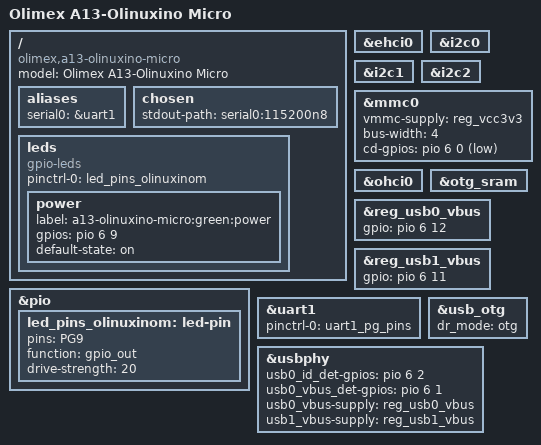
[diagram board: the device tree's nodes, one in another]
/*
 * Copyright 2012 Maxime Ripard <maxime.ripard@free-electrons.com>
 * Copyright 2013 Hans de Goede <hdegoede@redhat.com>
 *
 * This file is dual-licensed: you can use it either under the terms
 * of the GPL or the X11 license, at your option. Note that this dual
 * licensing only applies to this file, and not this project as a
 * whole.
 *
 *  a) This file is free software; you can redistribute it and/or
 *     modify it under the terms of the GNU General Public License as
 *     published by the Free Software Foundation; either version 2 of the
 *     License, or (at your option) any later version.
 *
 *     This file is distributed in the hope that it will be useful,
 *     but WITHOUT ANY WARRANTY; without even the implied warranty of
 *     MERCHANTABILITY or FITNESS FOR A PARTICULAR PURPOSE.  See the
 *     GNU General Public License for more details.
 *
 * Or, alternatively,
 *
 *  b) Permission is hereby granted, free of charge, to any person
 *     obtaining a copy of this software and associated documentation
 *     files (the "Software"), to deal in the Software without
 *     restriction, including without limitation the rights to use,
 *     copy, modify, merge, publish, distribute, sublicense, and/or
 *     sell copies of the Software, and to permit persons to whom the
 *     Software is furnished to do so, subject to the following
 *     conditions:
 *
 *     The above copyright notice and this permission notice shall be
 *     included in all copies or substantial portions of the Software.
 *
 *     THE SOFTWARE IS PROVIDED "AS IS", WITHOUT WARRANTY OF ANY KIND,
 *     EXPRESS OR IMPLIED, INCLUDING BUT NOT LIMITED TO THE WARRANTIES
 *     OF MERCHANTABILITY, FITNESS FOR A PARTICULAR PURPOSE AND
 *     NONINFRINGEMENT. IN NO EVENT SHALL THE AUTHORS OR COPYRIGHT
 *     HOLDERS BE LIABLE FOR ANY CLAIM, DAMAGES OR OTHER LIABILITY,
 *     WHETHER IN AN ACTION OF CONTRACT, TORT OR OTHERWISE, ARISING
 *     FROM, OUT OF OR IN CONNECTION WITH THE SOFTWARE OR THE USE OR
 *     OTHER DEALINGS IN THE SOFTWARE.
 */

/dts-v1/;
#include "sun5i-a13.dtsi"
#include "sunxi-common-regulators.dtsi"

#include <dt-bindings/gpio/gpio.h>

/ {
	model = "Olimex A13-Olinuxino Micro";
	compatible = "olimex,a13-olinuxino-micro", "allwinner,sun5i-a13";

	aliases {
		serial0 = &uart1;
	};

	chosen {
		stdout-path = "serial0:115200n8";
	};

	leds {
		compatible = "gpio-leds";
		pinctrl-names = "default";
		pinctrl-0 = <&led_pins_olinuxinom>;

		power {
			label = "a13-olinuxino-micro:green:power";
			gpios = <&pio 6 9 GPIO_ACTIVE_HIGH>;
			default-state = "on";
		};
	};
};

&ehci0 {
	status = "okay";
};

&i2c0 {
	status = "okay";
};

&i2c1 {
	status = "okay";
};

&i2c2 {
	status = "okay";
};

&mmc0 {
	vmmc-supply = <&reg_vcc3v3>;
	bus-width = <4>;
	cd-gpios = <&pio 6 0 GPIO_ACTIVE_LOW>; /* PG0 */
	status = "okay";
};

&ohci0 {
	status = "okay";
};

&otg_sram {
	status = "okay";
};

&pio {
	led_pins_olinuxinom: led-pin {
		pins = "PG9";
		function = "gpio_out";
		drive-strength = <20>;
	};
};

&reg_usb0_vbus {
	gpio = <&pio 6 12 GPIO_ACTIVE_HIGH>;
	status = "okay";
};

&reg_usb1_vbus {
	gpio = <&pio 6 11 GPIO_ACTIVE_HIGH>;
	status = "okay";
};

&uart1 {
	pinctrl-names = "default";
	pinctrl-0 = <&uart1_pg_pins>;
	status = "okay";
};

&usb_otg {
	dr_mode = "otg";
	status = "okay";
};

&usbphy {
	usb0_id_det-gpios = <&pio 6 2 (GPIO_ACTIVE_HIGH | GPIO_PULL_UP)>; /* PG2 */
	usb0_vbus_det-gpios = <&pio 6 1 (GPIO_ACTIVE_HIGH | GPIO_PULL_DOWN)>; /* PG1 */
	usb0_vbus-supply = <&reg_usb0_vbus>;
	usb1_vbus-supply = <&reg_usb1_vbus>;
	status = "okay";
};
